# CC3200 register map
Vendor: Texas Instruments; Series: SimpleLink; File version: 1.0
CPU: CM4 r0p1, little endian, MPU, no FPU, 3 interrupt priority bits
Registers are 32-bit, read-write, reset 0x0 unless marked. A register's access mark holds for its fields unless they carry their own. Offsets are from the block's base; [hi:lo] are bit positions; {n}, {i} and the like mark numbered series.

## I2C — I2CA0
Base 0x40020000
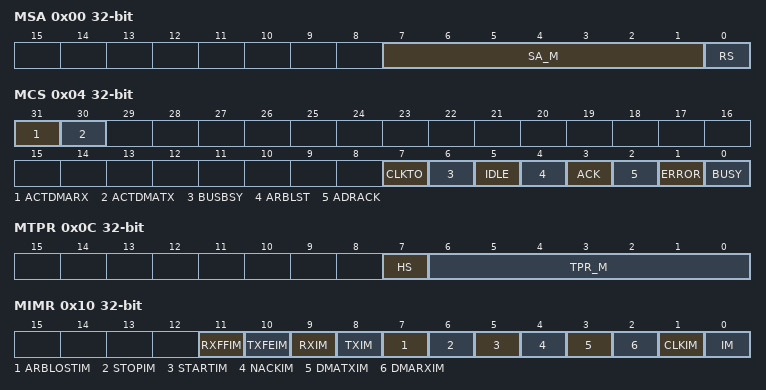
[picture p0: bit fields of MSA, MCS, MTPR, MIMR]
0x00 MSA — I2C_MSA
  [7:1] SA_M — I2C_MSA
  [0] RS — I2C_MSA
0x04 MCS — I2C_MCS
  [31] ACTDMARX — I2C_MCS
  [30] ACTDMATX — I2C_MCS
  [7] CLKTO — I2C_MCS
  [6] BUSBSY — I2C_MCS
  [5] IDLE — I2C_MCS
  [4] ARBLST — I2C_MCS
  [3] ACK — I2C_MCS
  [2] ADRACK — I2C_MCS
  [1] ERROR — I2C_MCS
  [0] BUSY — I2C_MCS
0x08 MDR — I2C_MDR
  [7:0] DATA_M
0x0C MTPR — I2C_MTPR
  [7] HS — I2C_MTPR
  [6:0] TPR_M — I2C_MTPR
0x10 MIMR — I2C_MIMR
  [11] RXFFIM — I2C_MIMR
  [10] TXFEIM — I2C_MIMR
  [9] RXIM — I2C_MIMR
  [8] TXIM — I2C_MIMR
  [7] ARBLOSTIM — I2C_MIMR
  [6] STOPIM — I2C_MIMR
  [5] STARTIM — I2C_MIMR
  [4] NACKIM — I2C_MIMR
  [3] DMATXIM — I2C_MIMR
  [2] DMARXIM — I2C_MIMR
  [1] CLKIM — I2C_MIMR
  [0] IM — I2C_MIMR
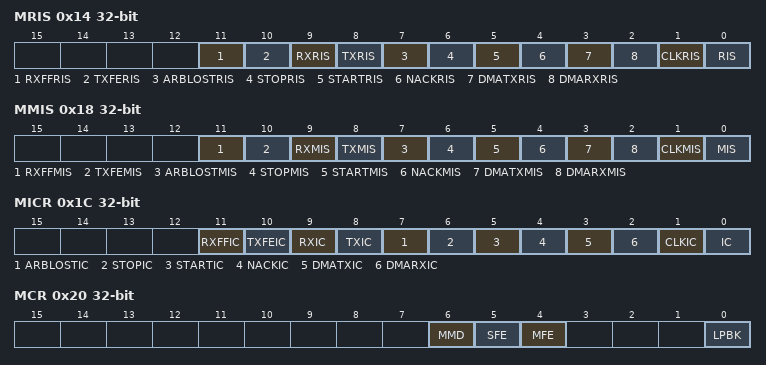
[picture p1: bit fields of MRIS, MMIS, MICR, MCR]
0x14 MRIS — I2C_MRIS
  [11] RXFFRIS — I2C_MRIS
  [10] TXFERIS — I2C_MRIS
  [9] RXRIS — I2C_MRIS
  [8] TXRIS — I2C_MRIS
  [7] ARBLOSTRIS — I2C_MRIS
  [6] STOPRIS — I2C_MRIS
  [5] STARTRIS — I2C_MRIS
  [4] NACKRIS — I2C_MRIS
  [3] DMATXRIS — I2C_MRIS
  [2] DMARXRIS — I2C_MRIS
  [1] CLKRIS — I2C_MRIS
  [0] RIS — I2C_MRIS
0x18 MMIS — I2C_MMIS
  [11] RXFFMIS — I2C_MMIS
  [10] TXFEMIS — I2C_MMIS
  [9] RXMIS — I2C_MMIS
  [8] TXMIS — I2C_MMIS
  [7] ARBLOSTMIS — I2C_MMIS
  [6] STOPMIS — I2C_MMIS
  [5] STARTMIS — I2C_MMIS
  [4] NACKMIS — I2C_MMIS
  [3] DMATXMIS — I2C_MMIS
  [2] DMARXMIS — I2C_MMIS
  [1] CLKMIS — I2C_MMIS
  [0] MIS — I2C_MMIS
0x1C MICR — I2C_MICR
  [11] RXFFIC — I2C_MICR
  [10] TXFEIC — I2C_MICR
  [9] RXIC — I2C_MICR
  [8] TXIC — I2C_MICR
  [7] ARBLOSTIC — I2C_MICR
  [6] STOPIC — I2C_MICR
  [5] STARTIC — I2C_MICR
  [4] NACKIC — I2C_MICR
  [3] DMATXIC — I2C_MICR
  [2] DMARXIC — I2C_MICR
  [1] CLKIC — I2C_MICR
  [0] IC — I2C_MICR
0x20 MCR — I2C_MCR
  [6] MMD — I2C_MCR
  [5] SFE — I2C_MCR
  [4] MFE — I2C_MCR
  [0] LPBK — I2C_MCR
0x24 MCLKOCNT — I2C_MCLKOCNT
  [7:0] CNTL_M
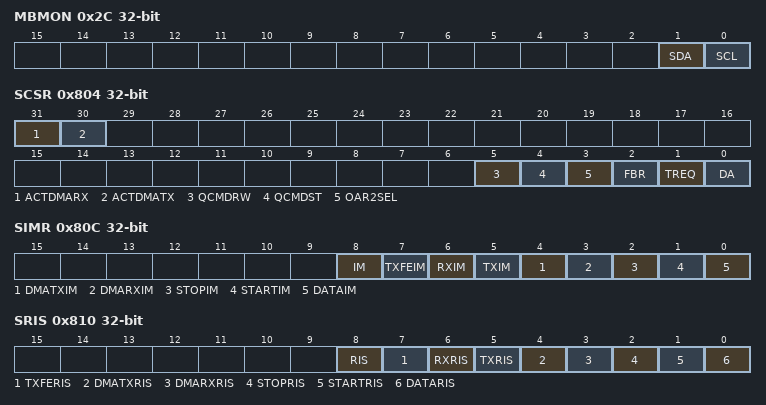
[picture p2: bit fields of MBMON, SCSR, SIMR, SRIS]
0x2C MBMON — I2C_MBMON
  [1] SDA — I2C_MBMON
  [0] SCL — I2C_MBMON
0x30 MBLEN — I2C_MBLEN
  [7:0] CNTL_M
0x34 MBCNT — I2C_MBCNT
  [7:0] CNTL_M
0x800 SOAR — I2C_SOAR
  [7] _OAR2EN — I2C_SOAR
  [6:0] OAR_M — I2C_SOAR
  [6:0] _OAR2_M — I2C_SOAR
0x804 SCSR — I2C_SCSR
  [31] ACTDMARX — I2C_SCSR
  [30] ACTDMATX — I2C_SCSR
  [5] QCMDRW — I2C_SCSR
  [4] QCMDST — I2C_SCSR
  [3] OAR2SEL — I2C_SCSR
  [2] FBR — I2C_SCSR
  [1] TREQ — I2C_SCSR
  [0] DA — I2C_SCSR
0x808 SDR — I2C_SDR
  [7:0] DATA_M
0x80C SIMR — I2C_SIMR
  [8] IM — I2C_SIMR
  [7] TXFEIM — I2C_SIMR
  [6] RXIM — I2C_SIMR
  [5] TXIM — I2C_SIMR
  [4] DMATXIM — I2C_SIMR
  [3] DMARXIM — I2C_SIMR
  [2] STOPIM — I2C_SIMR
  [1] STARTIM — I2C_SIMR
  [0] DATAIM — I2C_SIMR
0x810 SRIS — I2C_SRIS
  [8] RIS — I2C_SRIS
  [7] TXFERIS — I2C_SRIS
  [6] RXRIS — I2C_SRIS
  [5] TXRIS — I2C_SRIS
  [4] DMATXRIS — I2C_SRIS
  [3] DMARXRIS — I2C_SRIS
  [2] STOPRIS — I2C_SRIS
  [1] STARTRIS — I2C_SRIS
  [0] DATARIS — I2C_SRIS
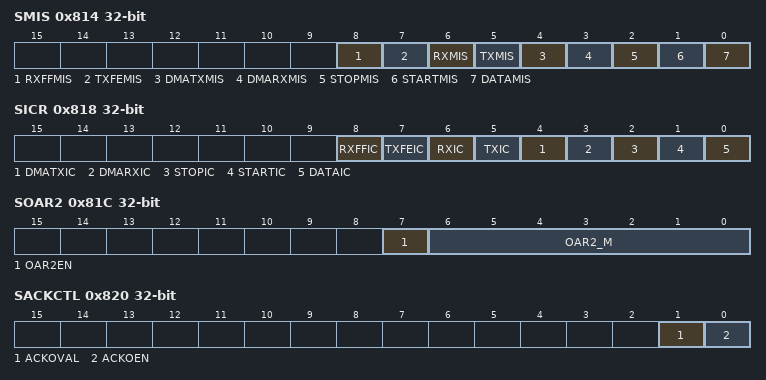
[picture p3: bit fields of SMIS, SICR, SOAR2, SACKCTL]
0x814 SMIS — I2C_SMIS
  [8] RXFFMIS — I2C_SMIS
  [7] TXFEMIS — I2C_SMIS
  [6] RXMIS — I2C_SMIS
  [5] TXMIS — I2C_SMIS
  [4] DMATXMIS — I2C_SMIS
  [3] DMARXMIS — I2C_SMIS
  [2] STOPMIS — I2C_SMIS
  [1] STARTMIS — I2C_SMIS
  [0] DATAMIS — I2C_SMIS
0x818 SICR — I2C_SICR
  [8] RXFFIC — I2C_SICR
  [7] TXFEIC — I2C_SICR
  [6] RXIC — I2C_SICR
  [5] TXIC — I2C_SICR
  [4] DMATXIC — I2C_SICR
  [3] DMARXIC — I2C_SICR
  [2] STOPIC — I2C_SICR
  [1] STARTIC — I2C_SICR
  [0] DATAIC — I2C_SICR
0x81C SOAR2 — I2C_SOAR2
  [7] OAR2EN — I2C_SOAR2
  [6:0] OAR2_M — I2C_SOAR2
0x820 SACKCTL — I2C_SACKCTL
  [1] ACKOVAL — I2C_SACKCTL
  [0] ACKOEN — I2C_SACKCTL
0xF00 FIFODATA — I2C_FIFODATA
  [7:0] DATA_M
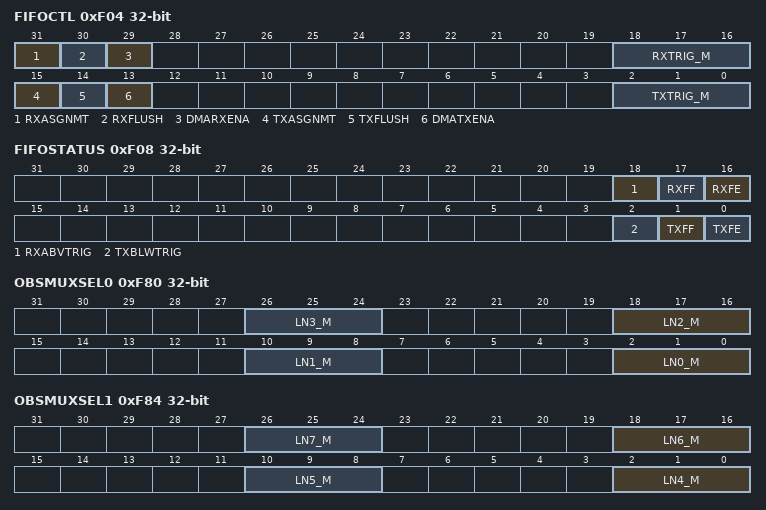
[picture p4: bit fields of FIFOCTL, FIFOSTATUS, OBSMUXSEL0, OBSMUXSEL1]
0xF04 FIFOCTL — I2C_FIFOCTL
  [31] RXASGNMT — I2C_FIFOCTL
  [30] RXFLUSH — I2C_FIFOCTL
  [29] DMARXENA — I2C_FIFOCTL
  [18:16] RXTRIG_M — I2C_FIFOCTL
  [15] TXASGNMT — I2C_FIFOCTL
  [14] TXFLUSH — I2C_FIFOCTL
  [13] DMATXENA — I2C_FIFOCTL
  [2:0] TXTRIG_M — I2C_FIFOCTL
0xF08 FIFOSTATUS — I2C_FIFOSTATUS
  [18] RXABVTRIG — I2C_FIFOSTATUS
  [17] RXFF — I2C_FIFOSTATUS
  [16] RXFE — I2C_FIFOSTATUS
  [2] TXBLWTRIG — I2C_FIFOSTATUS
  [1] TXFF — I2C_FIFOSTATUS
  [0] TXFE — I2C_FIFOSTATUS
0xF80 OBSMUXSEL0 — I2C_OBSMUXSEL0
  [8n+2:8n] LN{n}_M (n=0..3) — I2C_OBSMUXSEL0
0xF84 OBSMUXSEL1 — I2C_OBSMUXSEL1
  [8n-30:8n-32] LN{n}_M (n=4..7) — I2C_OBSMUXSEL1
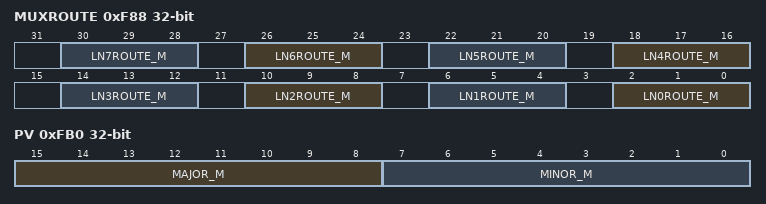
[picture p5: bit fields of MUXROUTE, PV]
0xF88 MUXROUTE — I2C_MUXROUTE
  [4n+2:4n] LN{n}ROUTE_M (n=0..7) — I2C_MUXROUTE
0xFB0 PV — I2C_PV
  [15:8] MAJOR_M — I2C_PV
  [7:0] MINOR_M — I2C_PV
0xFC0 PP — I2C_PP
  [0] HS
0xFC4 PC — I2C_PC
  [0] HS
0xFC8 CC — I2C_CC
